# HDSC_HC32L150FX register map
Vendor: HDSC Co.Ltd; Series: ARMCM0P; File version: 1.2
CPU: CM0 r0p0, little endian, no MPU, no FPU, 3 interrupt priority bits
Registers are 8-bit, read-write, reset 0x0 unless marked. A register's access mark holds for its fields unless they carry their own. Offsets are from the block's base; [hi:lo] are bit positions; {n}, {i} and the like mark numbered series.

## MSC0_I2C — desc MSC_I2C
Base 0x40038000
Same registers: MSC4_I2C 0x40037000, MSC5_I2C 0x40037100, MSC6_I2C 0x40037200, MSC1_I2C 0x40038100, MSC2_I2C 0x40038200
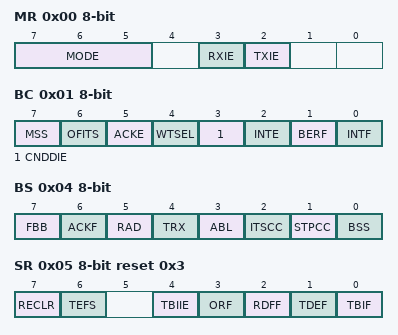
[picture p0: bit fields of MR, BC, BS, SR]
0x00 MR
  [7:5] MODE, [3] RXIE, [2] TXIE
0x01 BC
  [7] MSS, [6] OFITS, [5] ACKE, [4] WTSEL, [3] CNDDIE, [2] INTE, [1] BERF ro, [0] INTF
0x04 BS
  [7] FBB ro, [6] ACKF ro, [5] RAD ro, [4] TRX ro, [3] ABL ro, [2] ITSCC, [1] STPCC, [0] BSS ro
0x05 SR reset 0x3
  [7] RECLR, [6] TEFS, [4] TBIIE, [3] ORF ro, [2] RDFF ro, [1] TDEF ro, [0] TBIF ro
0x08 RXDR 16-bit ro (reset mask 0xFF)
0x08 TXDR 16-bit wo reset 0xFF (reset mask 0xFF)
0x0C BRS 16-bit
  [14:0] BRS
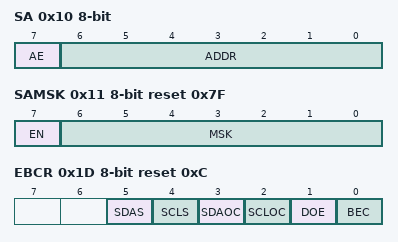
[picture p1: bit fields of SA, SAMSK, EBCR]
0x10 SA
  [7] AE, [6:0] ADDR
0x11 SAMSK reset 0x7F
  [7] EN, [6:0] MSK
0x1D EBCR reset 0xC
  [5] SDAS ro, [4] SCLS ro, [3] SDAOC, [2] SCLOC, [1] DOE, [0] BEC

## MSC0_SPI — desc MSC_SPI
Base 0x40038000; alternate view of MSC0_I2C
Same registers: MSC4_SPI 0x40037000 (alternate view of MSC4_I2C), MSC5_SPI 0x40037100 (alternate view of MSC5_I2C), MSC6_SPI 0x40037200 (alternate view of MSC6_I2C), MSC1_SPI 0x40038100 (alternate view of MSC1_I2C), MSC2_SPI 0x40038200 (alternate view of MSC2_I2C)
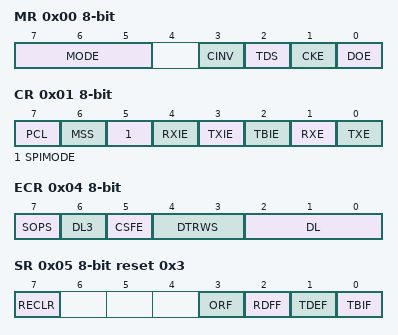
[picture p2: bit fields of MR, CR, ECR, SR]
0x00 MR
  [7:5] MODE, [3] CINV, [2] TDS, [1] CKE, [0] DOE
0x01 CR
  [7] PCL, [6] MSS, [5] SPIMODE, [4] RXIE, [3] TXIE, [2] TBIE, [1] RXE, [0] TXE
0x04 ECR
  [7] SOPS, [6] DL3, [5] CSFE, [4:3] DTRWS, [2:0] DL
0x05 SR reset 0x3
  [7] RECLR, [3] ORF ro, [2] RDFF ro, [1] TDEF ro, [0] TBIF ro
0x08 RXDR 16-bit ro
0x08 TXDR 16-bit wo reset 0xFFFF
0x0C BRS 16-bit
  [14:0] BRS
0x1C CSTMG0
  [7:0] CSHDLY
0x1D CSTMG1
  [7:0] CSSDLY
0x20 CSTMG32 16-bit
  [15:0] CSDS
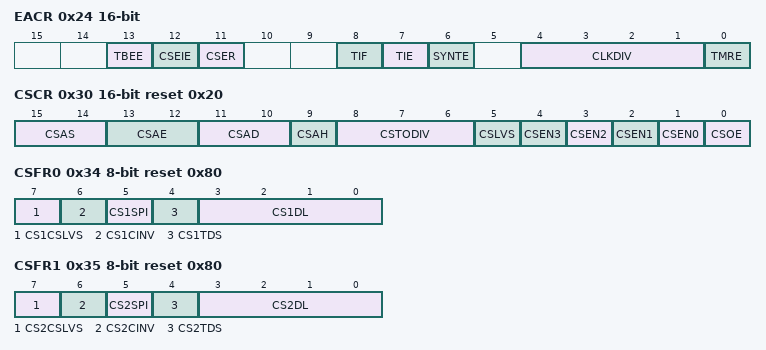
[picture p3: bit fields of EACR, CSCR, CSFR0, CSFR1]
0x24 EACR 16-bit
  [13] TBEE, [12] CSEIE, [11] CSER, [8] TIF, [7] TIE, [6] SYNTE, [4:1] CLKDIV, [0] TMRE
0x28 TMR 16-bit ro
0x2C TMC 16-bit
0x30 CSCR 16-bit reset 0x20
  [15:14] CSAS, [13:12] CSAE, [11:10] CSAD ro, [9] CSAH, [8:6] CSTODIV, [5] CSLVS, [n+1] CSEN{n} (n=0..3), [0] CSOE
0x34 CSFR0 reset 0x80
  [7] CS1CSLVS, [6] CS1CINV, [5] CS1SPI, [4] CS1TDS, [3:0] CS1DL
0x35 CSFR1 reset 0x80
  [7] CS2CSLVS, [6] CS2CINV, [5] CS2SPI, [4] CS2TDS, [3:0] CS2DL
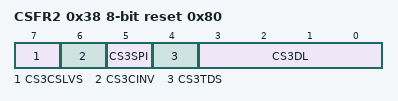
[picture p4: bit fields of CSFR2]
0x38 CSFR2 reset 0x80
  [7] CS3CSLVS, [6] CS3CINV, [5] CS3SPI, [4] CS3TDS, [3:0] CS3DL
0x3C TDTCNT0
0x3D TDTCNT1
0x40 TDTCNT2
0x41 TDTCNT3

## MSC0_UART — desc MSC_UART
Base 0x40038000; alternate view of MSC0_I2C
Same registers: MSC4_UART 0x40037000 (alternate view of MSC4_I2C), MSC5_UART 0x40037100 (alternate view of MSC5_I2C), MSC6_UART 0x40037200 (alternate view of MSC6_I2C), MSC1_UART 0x40038100 (alternate view of MSC1_I2C), MSC2_UART 0x40038200 (alternate view of MSC2_I2C)
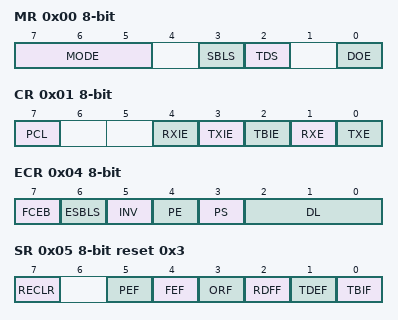
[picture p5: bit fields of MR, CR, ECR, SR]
0x00 MR
  [7:5] MODE, [3] SBLS, [2] TDS, [0] DOE
0x01 CR
  [7] PCL, [4] RXIE, [3] TXIE, [2] TBIE, [1] RXE, [0] TXE
0x04 ECR
  [7] FCEB, [6] ESBLS, [5] INV, [4] PE, [3] PS, [2:0] DL
0x05 SR reset 0x3
  [7] RECLR, [5] PEF ro, [4] FEF ro, [3] ORF ro, [2] RDFF ro, [1] TDEF ro, [0] TBIF ro
0x08 RXDR 16-bit ro (reset mask 0x1FF)
0x08 TXDR 16-bit wo reset 0x1FF (reset mask 0x1FF)
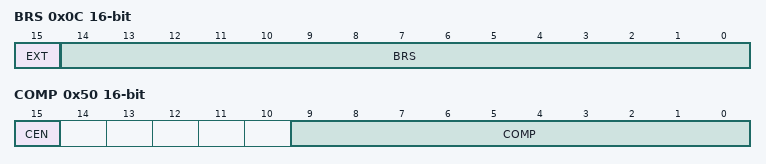
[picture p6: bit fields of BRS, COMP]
0x0C BRS 16-bit
  [15] EXT, [14:0] BRS
0x50 COMP 16-bit
  [15] CEN, [9:0] COMP

## OSC
Base 0x4002E000
0x00 HICR_TRMKEY 32-bit reset 0x1
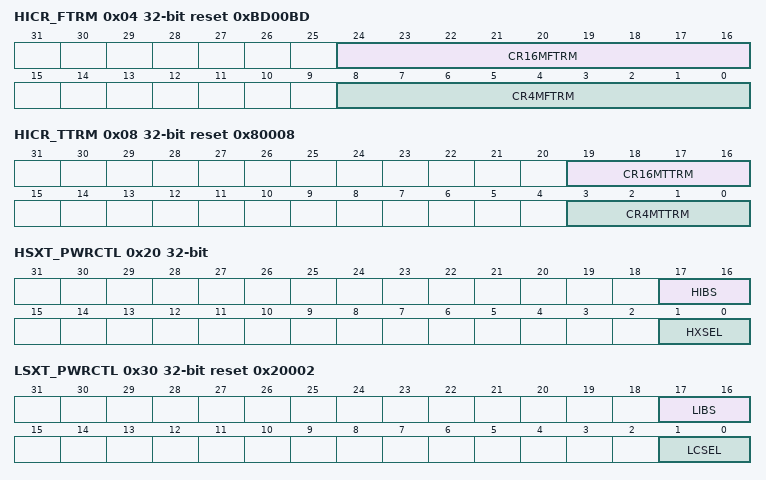
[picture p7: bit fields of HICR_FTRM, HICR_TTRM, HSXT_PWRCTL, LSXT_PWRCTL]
0x04 HICR_FTRM 32-bit reset 0xBD00BD
  [24:16] CR16MFTRM, [8:0] CR4MFTRM
0x08 HICR_TTRM 32-bit reset 0x80008
  [19:16] CR16MTTRM, [3:0] CR4MTTRM
0x0C HICR_FMC reset 0x1
  [1:0] FMC
0x10 HICR_CSR reset 0x1
  [2:0] CSR
0x20 HSXT_PWRCTL 32-bit
  [17:16] HIBS, [1:0] HXSEL
0x30 LSXT_PWRCTL 32-bit reset 0x20002
  [17:16] LIBS, [1:0] LCSEL

## PARITY
Base 0x4003C000
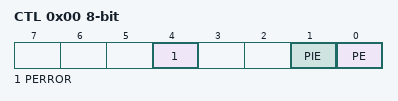
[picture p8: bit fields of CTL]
0x00 CTL
  [4] PERROR, [1] PIE, [0] PE
0x04 ADDR 32-bit

## PCG
Base 0x4003C100
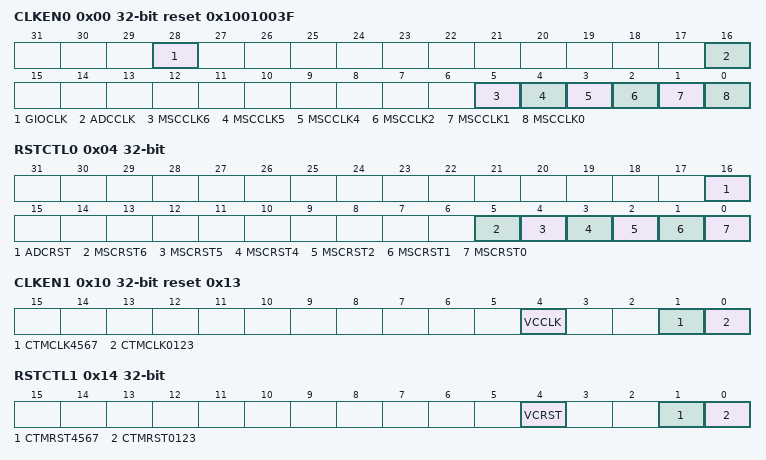
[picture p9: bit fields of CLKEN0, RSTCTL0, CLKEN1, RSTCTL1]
0x00 CLKEN0 32-bit reset 0x1001003F
  [28] GIOCLK, [16] ADCCLK, [5] MSCCLK6, [4] MSCCLK5, [3] MSCCLK4, [2] MSCCLK2, [1] MSCCLK1, [0] MSCCLK0
0x04 RSTCTL0 32-bit
  [16] ADCRST, [5] MSCRST6, [4] MSCRST5, [3] MSCRST4, [2] MSCRST2, [1] MSCRST1, [0] MSCRST0
0x10 CLKEN1 32-bit reset 0x13
  [4] VCCLK, [1] CTMCLK4567, [0] CTMCLK0123
0x14 RSTCTL1 32-bit
  [4] VCRST, [1] CTMRST4567, [0] CTMRST0123
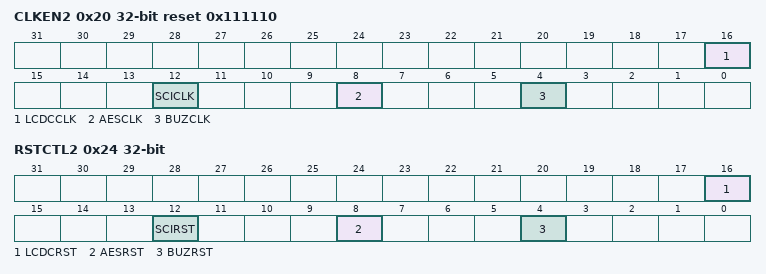
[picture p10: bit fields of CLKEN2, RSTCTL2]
0x20 CLKEN2 32-bit reset 0x111110
  [16] LCDCCLK, [12] SCICLK, [8] AESCLK, [4] BUZCLK
0x24 RSTCTL2 32-bit
  [16] LCDCRST, [12] SCIRST, [8] AESRST, [4] BUZRST

## RTC
Base 0x4003B000
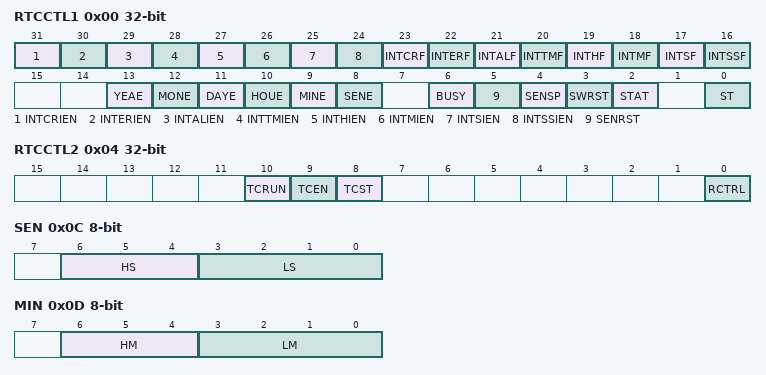
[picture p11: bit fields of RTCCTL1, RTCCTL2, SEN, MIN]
0x00 RTCCTL1 32-bit
  [31] INTCRIEN, [30] INTERIEN, [29] INTALIEN, [28] INTTMIEN, [27] INTHIEN, [26] INTMIEN, [25] INTSIEN, [24] INTSSIEN, [23] INTCRF, [22] INTERF, [21] INTALF, [20] INTTMF, [19] INTHF, [18] INTMF, [17] INTSF, [16] INTSSF, [13] YEAE, [12] MONE, [11] DAYE, [10] HOUE, [9] MINE, [8] SENE, [6] BUSY ro, [5] SENRST, [4] SENSP, [3] SWRST, [2] STAT ro, [0] ST
0x04 RTCCTL2 32-bit
  [10] TCRUN ro, [9] TCEN, [8] TCST, [0] RCTRL
0x08 CCS 32-bit
  [23:0] CC
0x0C SEN
  [6:4] HS, [3:0] LS
0x0D MIN
  [6:4] HM, [3:0] LM
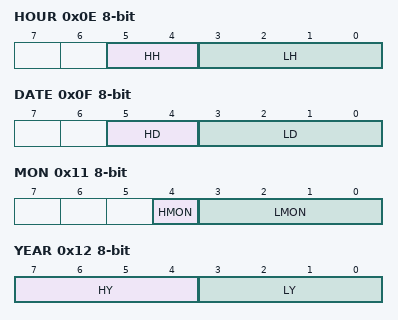
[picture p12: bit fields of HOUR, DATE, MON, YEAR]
0x0E HOUR
  [5:4] HH, [3:0] LH
0x0F DATE
  [5:4] HD, [3:0] LD
0x10 WEEK
  [2:0] WK
0x11 MON
  [4] HMON, [3:0] LMON
0x12 YEAR
  [7:4] HY, [3:0] LY
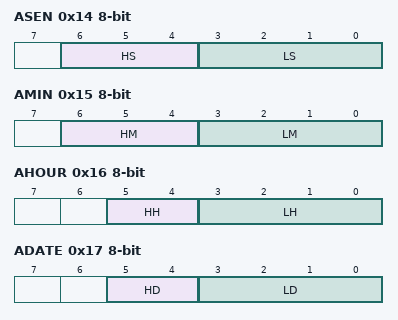
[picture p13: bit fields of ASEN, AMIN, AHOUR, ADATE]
0x14 ASEN
  [6:4] HS, [3:0] LS
0x15 AMIN
  [6:4] HM, [3:0] LM
0x16 AHOUR
  [5:4] HH, [3:0] LH
0x17 ADATE
  [5:4] HD, [3:0] LD
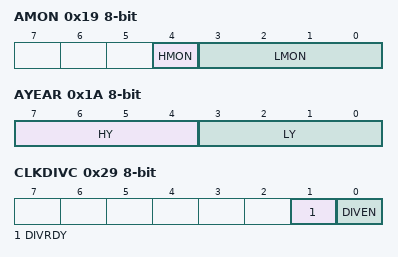
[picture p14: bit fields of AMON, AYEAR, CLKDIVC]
0x19 AMON
  [4] HMON, [3:0] LMON
0x1A AYEAR
  [7:4] HY, [3:0] LY
0x1C TVAL 32-bit
  [17:0] VAL
0x20 SCLKI
  [0] SCLKI
0x21 SCLKS ro
  [1:0] SCLKS
0x24 CALVAL 16-bit
  [9:0] CALVAL
0x26 CALEN
  [0] CALEN
0x28 CLKDIVX
  [3:0] DIVX
0x29 CLKDIVC
  [1] DIVRDY ro, [0] DIVEN
0x2C CALCYC 16-bit reset 0x13
  [8:0] CALCYC
0x30 RTCODIV
  [0] CODIV2

## SBSSR
Base 0x40025F00
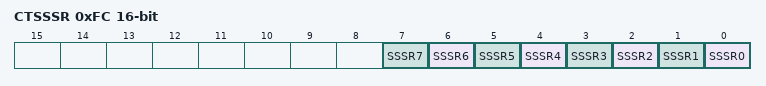
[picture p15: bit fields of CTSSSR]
0xFC CTSSSR 16-bit wo
  [n] SSSR{n} (n=0..7)

## SWWDT
Base 0x40012000
0x00 WDT_LD 32-bit reset 0xFFFFFFFF
0x04 WDT_VL 32-bit ro reset 0xFFFFFFFF
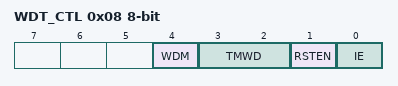
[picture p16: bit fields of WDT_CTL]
0x08 WDT_CTL
  [4] WDM, [3:2] TMWD, [1] RSTEN, [0] IE
0x0C WDT_INTCLR 32-bit
0x10 WDT_STA ro
  [0] STA
0x18 WDT_MDC
  [0] TRG
0xC00 WDT_LCK 32-bit

## UID
Base 0x40000200
0x00 UIDR0 32-bit ro
  [31:0] UID
0x04 UIDR1 32-bit ro
  [31:0] UID
0x08 UIDR2 32-bit ro
  [15:0] UID

## VC
Base 0x4003C300
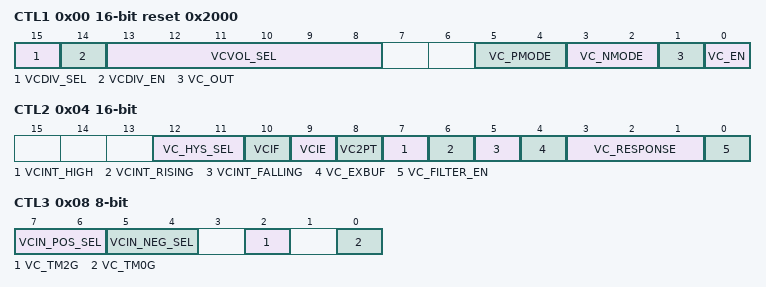
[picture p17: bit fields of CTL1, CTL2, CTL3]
0x00 CTL1 16-bit reset 0x2000
  [15] VCDIV_SEL, [14] VCDIV_EN, [13:8] VCVOL_SEL, [5:4] VC_PMODE, [3:2] VC_NMODE, [1] VC_OUT ro, [0] VC_EN
0x04 CTL2 16-bit
  [12:11] VC_HYS_SEL, [10] VCIF, [9] VCIE, [8] VC2PT, [7] VCINT_HIGH, [6] VCINT_RISING, [5] VCINT_FALLING, [4] VC_EXBUF, [3:1] VC_RESPONSE, [0] VC_FILTER_EN
0x08 CTL3
  [7:6] VCIN_POS_SEL, [5:4] VCIN_NEG_SEL, [2] VC_TM2G, [0] VC_TM0G

## WSUNIT
Base 0x40035000
0x00 LVD_CTRL1
  [7:4] LVD_VSET, [3:2] LVD_VIN, [1] LVD_SRST, [0] LVD_EN
0x04 LVD_CTRL2
  [6:5] LVD_IE, [4:2] LVD_F_SET, [1] LVD_F_EN, [0] LVD_HYS_EN
0x08 LVD_STR 16-bit ro
  [8] LVD_OUT, [0] LVD_IRQ
0x0C LVD_CLR reset 0x1
  [0] LVD_CLR
0x14 LVD2_CTL reset 0x7
  [4] LVD2_IE, [3:1] LVD2_VSET, [0] LVD2_EN
0x18 LVD2_STR 16-bit ro
  [9] LVD2_STA, [8] SENSE_STA, [0] LVD2_IRQ
0x1C LVD2_CLR reset 0x1
  [0] LVD2_CLR
0x20 LDO_CTL 32-bit reset 0x100
  [31:16] KEY wo, [8] AUTOSWEN
0x30 BGR_CTL
  [0] BGR_EN
0x100 CLK_CTL1
  [0] RTCE
0x104 CLK_CTL2 reset 0x5
  [4] UARTCKE, [2] WDTCKE, [1] LCDCKE, [0] RTCCKE
0x108 MOSC_CTL reset 0x2
  [1:0] IMAINSEL
0x10C DS_RAMP
  [0] RAMP
0x200 WAKE_RSR ro
  [1] RELVDR, [0] REINTX
0x204 WAKE_ISR ro
  [n+2] REWU{n}I (n=0..3), [1] RELVDI, [0] RERTCI
0x208 WAKE_IER
  [n+2] REWU{n}E (n=0..3), [1] RELVDE, [0] RERTCE
0x20C WAKE_LVR
  [n] WUI{n}LV (n=0..3)
{0x6FF+i} BUR{i:02} (i=1..16)
